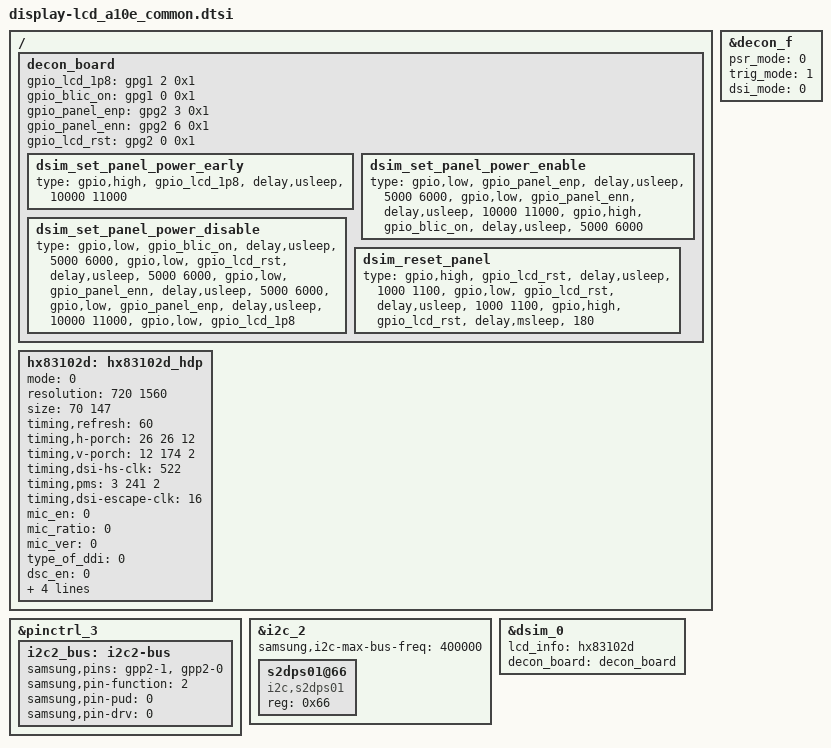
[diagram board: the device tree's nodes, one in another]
/*
 * SAMSUNG LCD Panel Device Tree Source
 *
 * Copyright (c) 2016 Samsung Electronics Co., Ltd.
 *		http://www.samsung.com
 *
 * This program is free software; you can redistribute it and/or modify
 * it under the terms of the GNU General Public License version 2 as
 * published by the Free Software Foundation.
*/

/ {
	fragment@lcd {
		target-path = "/";
		__overlay__ {
			decon_board: decon_board {
				gpio_lcd_1p8 = <&gpg1 2 0x1>;
				gpio_blic_on = <&gpg1 0 0x1>;
				gpio_panel_enp = <&gpg2 3 0x1>;
				gpio_panel_enn = <&gpg2 6 0x1>;
				gpio_lcd_rst = <&gpg2 0 0x1>;

				dsim_set_panel_power_early {
					type =
					"gpio,high",	"gpio_lcd_1p8",
					"delay,usleep",	"10000 11000";
				};
				dsim_set_panel_power_enable {
					type =
					"gpio,low",	"gpio_panel_enp",
					"delay,usleep",	"5000 6000",
					"gpio,low",	"gpio_panel_enn",
					"delay,usleep",	"10000 11000",
					"gpio,high",	"gpio_blic_on",
					"delay,usleep",	"5000 6000";
				};
				dsim_set_panel_power_disable {
					type =
					"gpio,low",	"gpio_blic_on",
					"delay,usleep",	"5000 6000",
					"gpio,low",	"gpio_lcd_rst",
					"delay,usleep",	"5000 6000",
					"gpio,low",	"gpio_panel_enn",
					"delay,usleep",	"5000 6000",
					"gpio,low",	"gpio_panel_enp",
					"delay,usleep",	"10000 11000",
					"gpio,low",	"gpio_lcd_1p8";
				};
				dsim_reset_panel {
					type =
					"gpio,high",	"gpio_lcd_rst",
					"delay,usleep",	"1000 1100",
					"gpio,low",	"gpio_lcd_rst",
					"delay,usleep",	"1000 1100",
					"gpio,high",	"gpio_lcd_rst",
					"delay,msleep",	"180";
				};
			};

			hx83102d: hx83102d_hdp {
				mode = <0>; /* 0: video mode, 1: DP command mode, 2: MIPI command mode */
				resolution = <720 1560>;
				size = <70 147>;	/* 69.5 x 147.2 */
				timing,refresh = <60>;
				/* dsim H porch : HBP, HFP, HSA */
				timing,h-porch = <26 26 12>;
				/* dsim V porch : VBP, VFP, VSA */
				timing,v-porch = <12 174 2>;
				timing,dsi-hs-clk = <522>;
				timing,pms = <3 241 2>;
				timing,dsi-escape-clk = <16>;
				mic_en = <0>;		/* 0: Disable, 1: Enable */
				mic_ratio = <0>;	/* 0: 1/2 mic, 1: 1/3 mic */
				mic_ver = <0>;		/* 0: mic v1.1, 1: v1.2, 2: v2.0 */
				type_of_ddi = <0>;	/* 0: Samsung Mobile, 1: MAGNA, 2: Normal(Etc) */
				dsc_en = <0>;		/* 0: Disable, 1: Enable */
				dsc_cnt = <0>;		/* used DSC count */
				dsc_slice_num = <0>;	/* count of dsc slice */
				data_lane = <4>;	/* number of using data lane */
				vt_compensation = <460>;	/* for difference between wordclk and vclk at video mode */
			};
		};
	};
};

&pinctrl_3 {
	i2c2_bus: i2c2-bus {
		samsung,pins = "gpp2-1", "gpp2-0";
		samsung,pin-function = <2>;
		samsung,pin-pud = <0>;
		samsung,pin-drv = <0>;
	};
};

&i2c_2 {
	status = "okay";
	samsung,i2c-max-bus-freq = <400000>;

	s2dps01@66 {
		compatible = "i2c,s2dps01";
		reg = <0x66>;
	};
};

&dsim_0 {
	lcd_info = <&hx83102d>;
	decon_board = <&decon_board>;
};

&decon_f {
	psr_mode = <0>;	/* 0: video mode, 1: DP command mode, 2: MIPI command mode */
	trig_mode = <1>;	/* 0: hw trigger, 1: sw trigger */
	dsi_mode = <0>;	/* 0: single dsi, 1: dual dsi */
};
